# ATSAML22N16A device description
Architecture: CORTEX-M0PLUS; Family: SAML; Series: SAML22
Registers are 32-bit, read-write, reset 0x0 unless marked. A register's access mark holds for its fields unless they carry their own. Offsets are from the block's base; [hi:lo] are bit positions; lines under a group give offsets from that group; {n}, {i} and the like mark numbered series; <NAME> marks a mode.

## PORT — Port Module
Instances: PORT 0x41006000, PORT_IOBUS 0x60000000
{0x0+0x80*i} GROUP[{i}] (i=0..2) group
  0x00 DIR — Data Direction
  0x04 DIRCLR (atomic clear of DIR) — Data Direction Clear
  0x08 DIRSET (atomic set of DIR) — Data Direction Set
  0x0C DIRTGL (atomic toggle of DIR) — Data Direction Toggle
  0x10 OUT — Data Output Value
  0x14 OUTCLR (atomic clear of OUT) — Data Output Value Clear
  0x18 OUTSET (atomic set of OUT) — Data Output Value Set
  0x1C OUTTGL (atomic toggle of OUT) — Data Output Value Toggle
  0x20 IN ro — Data Input Value
  0x24 CTRL — Control
    [31:0] SAMPLING — Input Sampling Mode
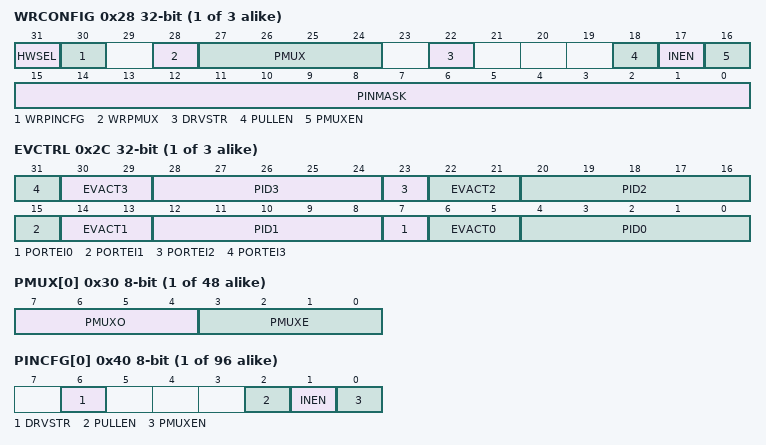
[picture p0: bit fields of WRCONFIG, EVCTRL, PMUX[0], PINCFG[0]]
  0x28 WRCONFIG wo — Write Configuration
    [31] HWSEL — Half-Word Select
    [30] WRPINCFG — Write PINCFG Registers
    [28] WRPMUX — Write PMUX Registers
    [27:24] PMUX — Peripheral Multiplexing Template
    [22] DRVSTR — Output Driver Strength Selection
    [18] PULLEN — Pull Enable
    [17] INEN — Input Enable
    [16] PMUXEN — Select Peripheral Multiplexer
    [15:0] PINMASK — Pin Mask for Multiple Pin Configuration
  0x2C EVCTRL — Event Input Control
    [8n+7] PORTEI{n} (n=0..3) — Port Event Enable Input {n}
    [30:29] EVACT3 — Port Event Action 3
    [8n+4:8n] PID{n} (n=0..3) — Port Event Pin Identifier {n}
    [22:21] EVACT2 — Port Event Action 2
    [14:13] EVACT1 — Port Event Action 1
    [6:5] EVACT0 — Port Event Action 0
      0=OUT (Event output to pin); 1=SET (Set output register of pin on event); 2=CLR (Clear output register of pin on event); 3=TGL (Toggle output register of pin on event)
  {0x30+j} PMUX[{j}] (j=0..15) 8-bit — Peripheral Multiplexing n
    [7:4] PMUXO — Peripheral Multiplexing for Odd-Numbered Pin
    [3:0] PMUXE — Peripheral Multiplexing for Even-Numbered Pin
  {0x40+j} PINCFG[{j}] (j=0..31) 8-bit — Pin Configuration n
    [6] DRVSTR — Output Driver Strength Selection
    [2] PULLEN — Pull Enable
    [1] INEN — Input Enable
    [0] PMUXEN — Select Peripheral Multiplexer

## RSTC — Reset Controller
Instances: RSTC 0x40000C00
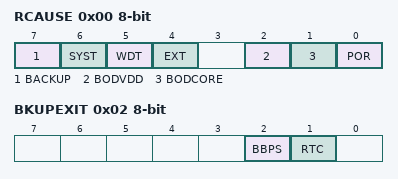
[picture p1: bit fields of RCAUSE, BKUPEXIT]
0x00 RCAUSE 8-bit ro reset not defined — Reset Cause
  [7] BACKUP — Backup Reset
  [6] SYST — System Reset Request
  [5] WDT — Watchdog Reset
  [4] EXT — External Reset
  [2] BODVDD — Brown Out VDD Detector Reset
  [1] BODCORE — Brown Out CORE Detector Reset
  [0] POR — Power On Reset
0x02 BKUPEXIT 8-bit ro — Backup Exit Source
  [2] BBPS — Battery Backup Power Switch
  [1] RTC — Real Timer Counter Interrupt

## TRNG — True Random Generator
Instances: TRNG 0x42004400
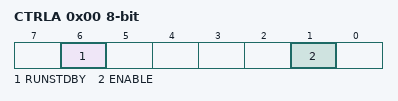
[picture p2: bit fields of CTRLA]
0x00 CTRLA 8-bit — Control A
  [6] RUNSTDBY — Run in Standby
  [1] ENABLE
0x04 EVCTRL 8-bit — Event Control
  [0] DATARDYEO — Data Ready Event Output
0x08 INTENCLR 8-bit (atomic clear) — Interrupt Enable Clear
  [0] DATARDY — Data Ready Interrupt Enable
0x09 INTENSET 8-bit (atomic set) — Interrupt Enable Set
  [0] DATARDY — Data Ready Interrupt Enable
0x0A INTFLAG 8-bit (atomic clear) — Interrupt Flag Status and Clear
  [0] DATARDY — Data Ready Interrupt Flag
0x20 DATA ro — Output Data

## USB_DESCRIPTOR — Universal Serial Bus
Modes: DEVICE when USB.CTRLA.MODE=0 (USB is Device)
{0x0+0x10*i} DEVICE_DESC_BANK[{i}] (i=0..1) <DEVICE> group
  0x00 ADDR <DEVICE> reset not defined — DEVICE_DESC_BANK Endpoint Bank, Adress of Data Buffer
    [31:0] ADDR — Adress of data buffer
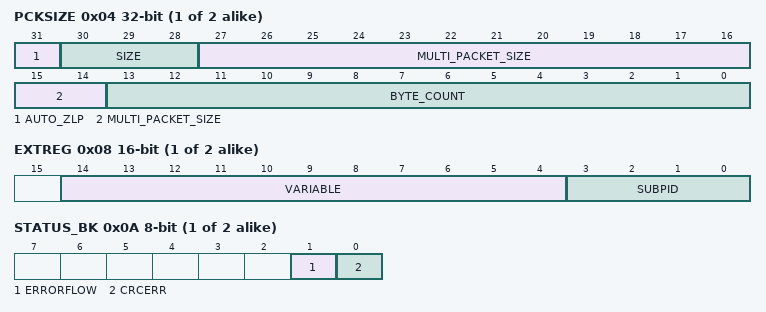
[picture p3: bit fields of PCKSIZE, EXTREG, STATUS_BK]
  0x04 PCKSIZE <DEVICE> reset not defined — DEVICE_DESC_BANK Endpoint Bank, Packet Size
    [31] AUTO_ZLP — Automatic Zero Length Packet
    [30:28] SIZE — Enpoint size
    [27:14] MULTI_PACKET_SIZE — Multi Packet In or Out size
    [13:0] BYTE_COUNT
  0x08 EXTREG <DEVICE> 16-bit reset not defined — DEVICE_DESC_BANK Endpoint Bank, Extended
    [14:4] VARIABLE — Variable field send with extended token
    [3:0] SUBPID — SUBPID field send with extended token
  0x0A STATUS_BK <DEVICE> 8-bit reset not defined — DEVICE_DESC_BANK Enpoint Bank, Status of Bank
    [1] ERRORFLOW — Error Flow Status
    [0] CRCERR — CRC Error Status

## Notices in the file
Copyright (c) 2018 Microchip Technology Inc.
SPDX-License-Identifier: Apache-2.0
Licensed under the Apache License, Version 2.0 (the "License");
you may not use this file except in compliance with the License.
You may obtain a copy of the License at
http://www.apache.org/licenses/LICENSE-2.0
Unless required by applicable law or agreed to in writing, software
distributed under the License is distributed on an "AS IS" BASIS,
WITHOUT WARRANTIES OR CONDITIONS OF ANY KIND, either express or implied.
See the License for the specific language governing permissions and
limitations under the License.
